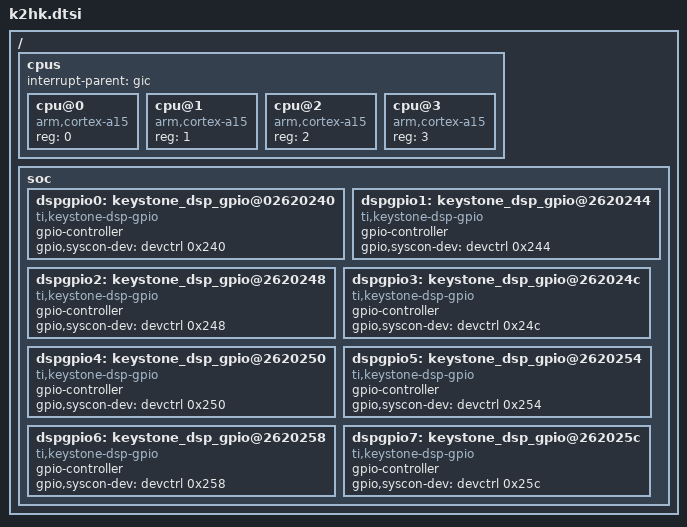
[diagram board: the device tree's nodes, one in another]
/*
 * Copyright 2013-2014 Texas Instruments, Inc.
 *
 * Keystone 2 Kepler/Hawking soc specific device tree
 *
 * This program is free software; you can redistribute it and/or modify
 * it under the terms of the GNU General Public License version 2 as
 * published by the Free Software Foundation.
 */

/ {
	cpus {
		#address-cells = <1>;
		#size-cells = <0>;

		interrupt-parent = <&gic>;

		cpu@0 {
			compatible = "arm,cortex-a15";
			device_type = "cpu";
			reg = <0>;
		};

		cpu@1 {
			compatible = "arm,cortex-a15";
			device_type = "cpu";
			reg = <1>;
		};

		cpu@2 {
			compatible = "arm,cortex-a15";
			device_type = "cpu";
			reg = <2>;
		};

		cpu@3 {
			compatible = "arm,cortex-a15";
			device_type = "cpu";
			reg = <3>;
		};
	};

	soc {
		/include/ "k2hk-clocks.dtsi"

		dspgpio0: keystone_dsp_gpio@02620240 {
			compatible = "ti,keystone-dsp-gpio";
			gpio-controller;
			#gpio-cells = <2>;
			gpio,syscon-dev = <&devctrl 0x240>;
		};

		dspgpio1: keystone_dsp_gpio@2620244 {
			compatible = "ti,keystone-dsp-gpio";
			gpio-controller;
			#gpio-cells = <2>;
			gpio,syscon-dev = <&devctrl 0x244>;
		};

		dspgpio2: keystone_dsp_gpio@2620248 {
			compatible = "ti,keystone-dsp-gpio";
			gpio-controller;
			#gpio-cells = <2>;
			gpio,syscon-dev = <&devctrl 0x248>;
		};

		dspgpio3: keystone_dsp_gpio@262024c {
			compatible = "ti,keystone-dsp-gpio";
			gpio-controller;
			#gpio-cells = <2>;
			gpio,syscon-dev = <&devctrl 0x24c>;
		};

		dspgpio4: keystone_dsp_gpio@2620250 {
			compatible = "ti,keystone-dsp-gpio";
			gpio-controller;
			#gpio-cells = <2>;
			gpio,syscon-dev = <&devctrl 0x250>;
		};

		dspgpio5: keystone_dsp_gpio@2620254 {
			compatible = "ti,keystone-dsp-gpio";
			gpio-controller;
			#gpio-cells = <2>;
			gpio,syscon-dev = <&devctrl 0x254>;
		};

		dspgpio6: keystone_dsp_gpio@2620258 {
			compatible = "ti,keystone-dsp-gpio";
			gpio-controller;
			#gpio-cells = <2>;
			gpio,syscon-dev = <&devctrl 0x258>;
		};

		dspgpio7: keystone_dsp_gpio@262025c {
			compatible = "ti,keystone-dsp-gpio";
			gpio-controller;
			#gpio-cells = <2>;
			gpio,syscon-dev = <&devctrl 0x25c>;
		};
	};
};
